# XMC4500 register map
Vendor: Infineon; File version: 1.2.0 (Reference Manual v1.2)
CPU: CM4 r2p0, little endian, MPU, FPU, 6 interrupt priority bits
Registers are 32-bit, read-write, reset 0x0 unless marked. A register's access mark holds for its fields unless they carry their own. Offsets are from the block's base; [hi:lo] are bit positions.

## RTC — Real Time Clock
Base 0x50004A00
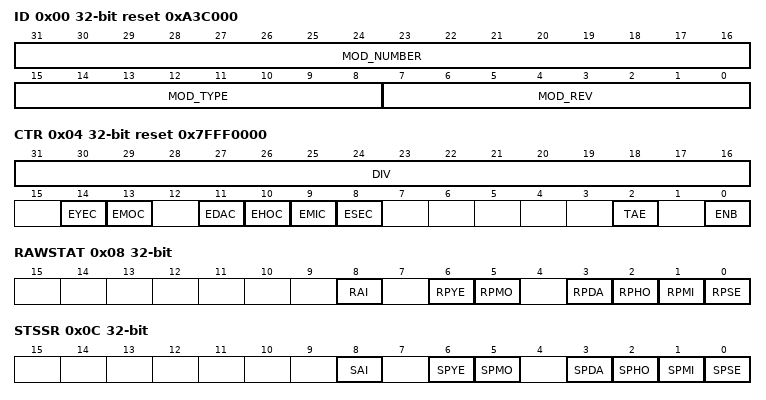
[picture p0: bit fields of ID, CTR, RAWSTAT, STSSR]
0x00 ID ro reset 0xA3C000 (reset mask 0xFFFFFF00) — RTC ID Register
  [31:16] MOD_NUMBER — Module Number
  [15:8] MOD_TYPE — Module Type
  [7:0] MOD_REV — Module Revision
0x04 CTR reset 0x7FFF0000 — RTC Control Register
  [31:16] DIV — RTC Clock Divider Value
  [14] EYEC — Enable Years Comparison for Hibernation Wake-up
  [13] EMOC — Enable Months Comparison for Hibernation Wake-up
  [11] EDAC — Enable Days Comparison for Hibernation Wake-up
  [10] EHOC — Enable Hours Comparison for Hibernation Wake-up
  [9] EMIC — Enable Minutes Comparison for Hibernation Wake-up
  [8] ESEC — Enable Seconds Comparison for Hibernation Wake-up
  [2] TAE — Timer Alarm Enable for Hibernation Wake-up
  [0] ENB — RTC Module Enable
0x08 RAWSTAT ro — RTC Raw Service Request Register
  [8] RAI — Raw Alarm Service Request
  [6] RPYE — Raw Periodic Years Service Request
  [5] RPMO — Raw Periodic Months Service Request
  [3] RPDA — Raw Periodic Days Service Request
  [2] RPHO — Raw Periodic Hours Service Request
  [1] RPMI — Raw Periodic Minutes Service Request
  [0] RPSE — Raw Periodic Seconds Service Request
0x0C STSSR ro — RTC Service Request Status Register
  [8] SAI — Alarm Service Request Status after Masking
  [6] SPYE — Periodic Years Service Request Status after Masking
  [5] SPMO — Periodic Months Service Request Status after Masking
  [3] SPDA — Periodic Days Service Request Status after Masking
  [2] SPHO — Periodic Hours Service Request Status after Masking
  [1] SPMI — Periodic Minutes Service Request Status after Masking
  [0] SPSE — Periodic Seconds Service Request Status after Masking
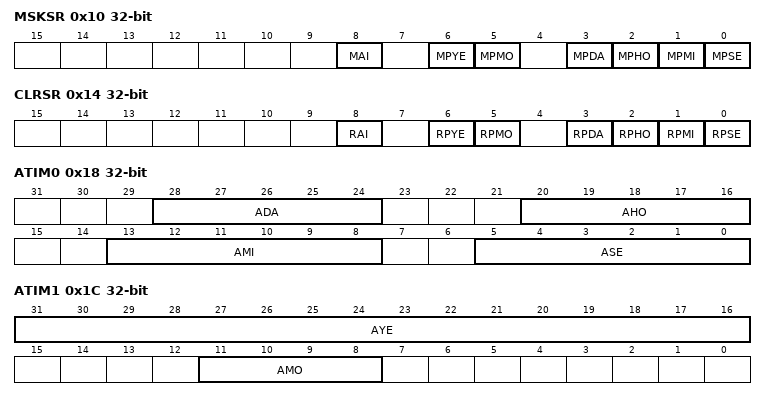
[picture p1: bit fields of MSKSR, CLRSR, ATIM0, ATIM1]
0x10 MSKSR — RTC Service Request Mask Register
  [8] MAI — Alarm Interrupt Mask
  [6] MPYE — Periodic Years Interrupt Mask
  [5] MPMO — Periodic Months Interrupt Mask
  [3] MPDA — Periodic Days Interrupt Mask
  [2] MPHO — Periodic Hours Interrupt Mask
  [1] MPMI — Periodic Minutes Interrupt Mask
  [0] MPSE — Periodic Seconds Interrupt Mask
0x14 CLRSR wo — RTC Clear Service Request Register
  [8] RAI — Alarm Interrupt Clear
  [6] RPYE — Periodic Years Interrupt Clear
  [5] RPMO — Periodic Months Interrupt Clear
  [3] RPDA — Periodic Days Interrupt Clear
  [2] RPHO — Periodic Hours Interrupt Clear
  [1] RPMI — Periodic Minutes Interrupt Clear
  [0] RPSE — Periodic Seconds Interrupt Clear
0x18 ATIM0 — RTC Alarm Time Register 0
  [28:24] ADA — Alarm Days Compare Value
  [20:16] AHO — Alarm Hours Compare Value
  [13:8] AMI — Alarm Minutes Compare Value
  [5:0] ASE — Alarm Seconds Compare Value
0x1C ATIM1 — RTC Alarm Time Register 1
  [31:16] AYE — Alarm Year Compare Value
  [11:8] AMO — Alarm Month Compare Value
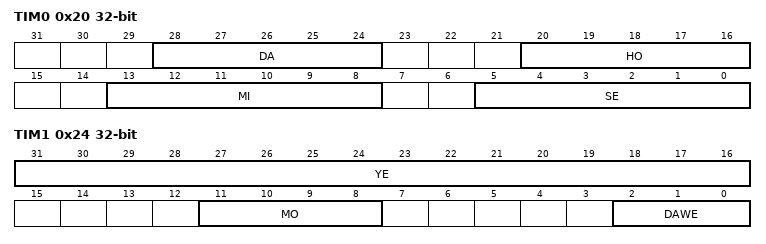
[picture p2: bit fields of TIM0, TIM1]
0x20 TIM0 — RTC Time Register 0
  [28:24] DA — Days Time Value
  [20:16] HO — Hours Time Value
  [13:8] MI — Minutes Time Value
  [5:0] SE — Seconds Time Value
0x24 TIM1 — RTC Time Register 1
  [31:16] YE — Year Time Value
  [11:8] MO — Month Time Value
  [2:0] DAWE — Days of Week Time Value

## SCU_CLK — System Control Unit
Base 0x50004600
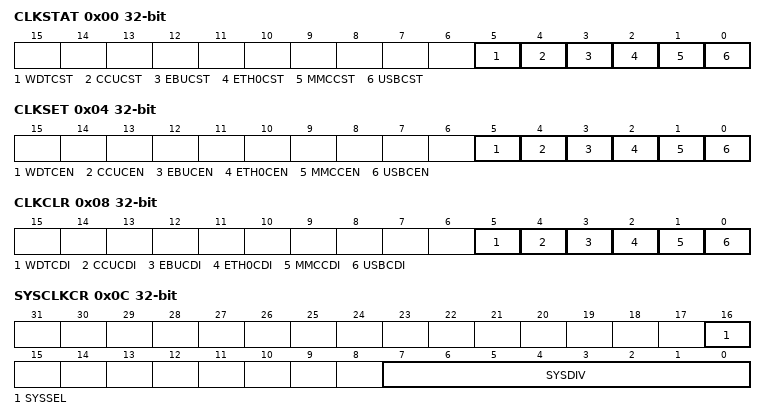
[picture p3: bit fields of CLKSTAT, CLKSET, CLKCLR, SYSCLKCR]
0x00 CLKSTAT ro — Clock Status Register
  [all] fields
    0=Clock disabled; 1=Clock enabled
  [5] WDTCST — WDT Clock Status
  [4] CCUCST — CCU Clock Status
  [3] EBUCST — EBU Clock Status
  [2] ETH0CST — Ethernet Clock Status
  [1] MMCCST — MMC Clock Status
  [0] USBCST — USB Clock Status
0x04 CLKSET wo
  [all] fields
    0=No effect; 1=Enable
  [5] WDTCEN — WDT Clock Enable
  [4] CCUCEN — CCU Clock Enable
  [3] EBUCEN — EBU Clock Enable
  [2] ETH0CEN — Ethernet Clock Enable
  [1] MMCCEN — MMC Clock Enable
  [0] USBCEN — USB Clock Enable
0x08 CLKCLR wo — CLK Clear Register
  [all] fields
    0=No effect; 1=Disable clock
  [5] WDTCDI — WDT Clock Disable
  [4] CCUCDI — CCU Clock Disable
  [3] EBUCDI — EBU Clock Disable
  [2] ETH0CDI — Ethernet Clock Disable
  [1] MMCCDI — MMC Clock Disable
  [0] USBCDI — USB Clock Disable
0x0C SYSCLKCR — System Clock Control Register
  [16] SYSSEL — System Clock Selection Value
    0=fOFI clock; 1=fPLL clock
  [7:0] SYSDIV — System Clock Division Value
0x10 CPUCLKCR — CPU Clock Control Register
  [0] CPUDIV — CPU Clock Divider Enable
    0=fCPU = fSYS; 1=fCPU = fSYS / 2
0x14 PBCLKCR — Peripheral Bus Clock Control Register
  [0] PBDIV — PB Clock Divider Enable
    0=fPERIPH = fCPU; 1=fPERIPH = fCPU / 2
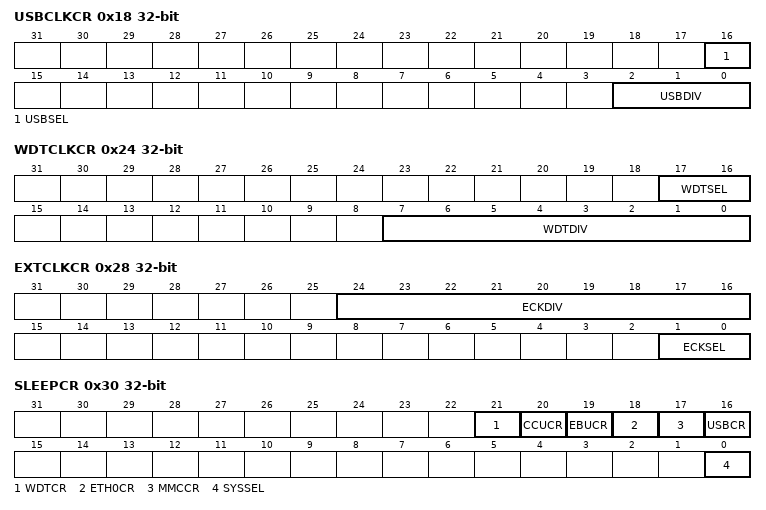
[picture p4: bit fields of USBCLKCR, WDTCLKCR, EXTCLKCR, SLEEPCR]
0x18 USBCLKCR — USB Clock Control Register
  [16] USBSEL — USB Clock Selection Value
    0=USB PLL Clock; 1=PLL Clock
  [2:0] USBDIV — USB Clock Divider Value
0x1C EBUCLKCR — EBU Clock Control Register
  [5:0] EBUDIV — EBU Clock Divider Value
0x20 CCUCLKCR — CCU Clock Control Register
  [0] CCUDIV — CCU Clock Divider Enable
    0=fCCU = fSYS; 1=fCCU = fSYS / 2
0x24 WDTCLKCR — WDT Clock Control Register
  [17:16] WDTSEL — WDT Clock Selection Value
    0=fOFI clock; 1=fSTDBY clock; 2=fPLL clock
  [7:0] WDTDIV — WDT Clock Divider Value
0x28 EXTCLKCR — External Clock Control
  [24:16] ECKDIV — External Clock Divider Value
  [1:0] ECKSEL — External Clock Selection Value
    0=fSYS clock; 2=fUSB clock; 3=fPLL clock divided according to ECKDIV bit field configuration
0x30 SLEEPCR — Sleep Control Register
  [21] WDTCR — WDT Clock Control
    0=Disable; 1=Enable
  [20] CCUCR — CCU Clock Control
    0=Disable; 1=Enable
  [19] EBUCR — EBU Clock Control
    0=Disable; 1=Enable
  [18] ETH0CR — Ethernet Clock Control
    0=Disable; 1=Enable
  [17] MMCCR — MMC Clock Control
    0=Disable; 1=Enable
  [16] USBCR — USB Clock Control
    0=Disable; 1=Enable
  [0] SYSSEL — System Clock Selection Value
    0=fOFI clock; 1=fPLL clock
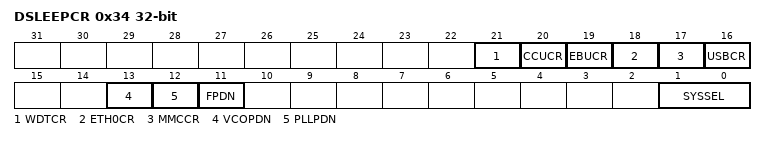
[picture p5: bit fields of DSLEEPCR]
0x34 DSLEEPCR — Deep Sleep Control Register
  [21] WDTCR — WDT Clock Control
    0=Disable; 1=Enable
  [20] CCUCR — CCU Clock Control
    0=Disable; 1=Enable
  [19] EBUCR — EBU Clock Control
    0=Disable; 1=Enable
  [18] ETH0CR — Ethernet Clock Control
    0=Disable; 1=Enable
  [17] MMCCR — MMC Clock Control
    0=Disable; 1=Enable
  [16] USBCR — USB Clock Control
    0=Disable; 1=Enable
  [13] VCOPDN — VCO Power Down
    1=Switch off VCO of main PLL; 0=No effect
  [12] PLLPDN — PLL Power Down
    1=Switch off main PLL; 0=No effect
  [11] FPDN — Flash Power Down
    1=Flash power down module; 0=No effect
  [1:0] SYSSEL — System Clock Selection Value
    0=fOFI clock; 1=fPLL clock
